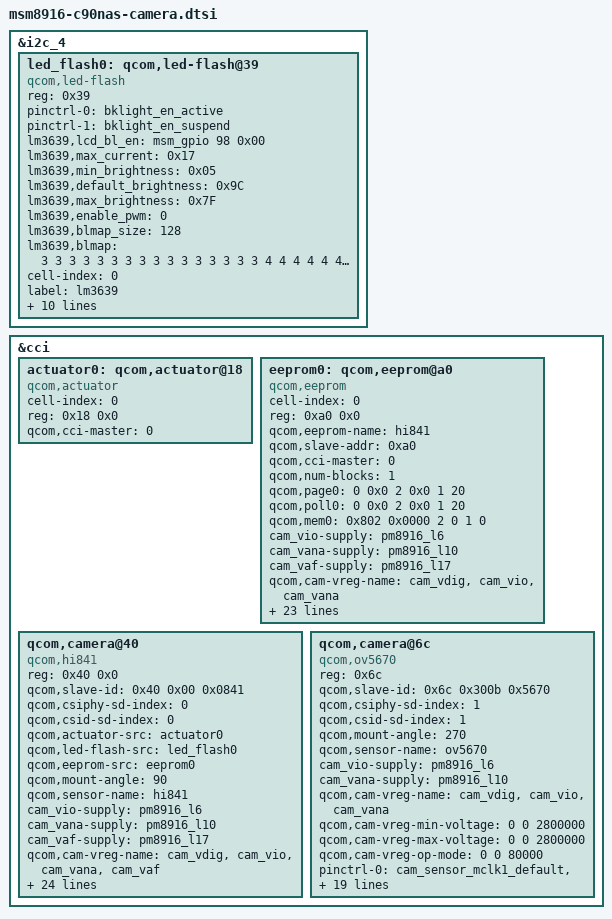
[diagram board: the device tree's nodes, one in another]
/*
 * Copyright (c) 2013, The Linux Foundation. All rights reserved.
 *
 * This program is free software; you can redistribute it and/or modify
 * it under the terms of the GNU General Public License version 2 and
 * only version 2 as published by the Free Software Foundation.
 *
 * This program is distributed in the hope that it will be useful,
 * but WITHOUT ANY WARRANTY; without even the implied warranty of
 * MERCHANTABILITY or FITNESS FOR A PARTICULAR PURPOSE.  See the
 * GNU General Public License for more details.
 */

&i2c_4 {
	led_flash0: qcom,led-flash@39 {
		compatible = "qcom,led-flash";
		status = "ok";
		reg = <0x39>;

		pinctrl-names = "default", "sleep";
		pinctrl-0 = <&bklight_en_active>;
		pinctrl-1 = <&bklight_en_suspend>;

		lm3639,lcd_bl_en = <&msm_gpio 98 0x00>;
		lm3639,max_current = <0x17>;
		lm3639,min_brightness = <0x05>;
		lm3639,default_brightness = <0x9C>;
		lm3639,max_brightness = <0x7F>;
		lm3639,enable_pwm = <0>;
		lm3639,blmap_size = <128>;
		lm3639,blmap = <
			3 3 3 3 3 3 3 3 3 3
			3 3 3 3 3 3 4 4 4 4
			4 4 4 5 5 5 5 5 6 6
			6 6 7 7 8 8 8 8 9 9
			10 10 10 11 11 12 13 13 13 14
			15 15 15 16 17 18 19 19 19 20
			21 22 23 23 24 25 26 26 27 28
			29 30 31 33 33 34 35 36 37 37
			38 39 41 42 43 43 45 46 48 49
			49 51 52 54 55 57 57 59 60 62
			64 64 66 67 69 71 73 73 75 77
			79 81 81 83 85 88 88 90 92 94
			96 99 101 101 104 106 108 111>;

		cell-index = <0>;
		label                   = "lm3639";
		qcom,flash-name         = "lm3639";
		qcom,slave-id           = <0x39 0x00 0x0011>;
		qcom,flash-type         = <1>;              // LED_FLASH
		qcom,gpio-no-mux        = <0>;
		gpios                   = <&msm_gpio 31 0>; // FLASH_STROBE_TRIG, GPIO 31
		qcom,gpio-flash-en      = <0>;
		qcom,gpio-req-tbl-num   = <0>;
		qcom,gpio-req-tbl-flags = <0>;
		qcom,gpio-req-tbl-label = "FLASH_EN";
		qcom,cci-master = <0>;
	};
};

&cci {

	actuator0: qcom,actuator@18 {
		cell-index = <0>;
		reg = <0x18 0x0>;
		compatible = "qcom,actuator";
		qcom,cci-master = <0>;
	};

	eeprom0: qcom,eeprom@a0 {
		cell-index = <0>;
		reg = <0xa0 0x0>;
		qcom,eeprom-name = "hi841";
		compatible = "qcom,eeprom";
		qcom,slave-addr = <0xa0>;
		qcom,cci-master = <0>;
		qcom,num-blocks = <1>;

		qcom,page0 = <0 0x0 2 0x0 1 20>;
		qcom,poll0 = <0 0x0 2 0x0 1 20>;
		qcom,mem0 = <0x802 0x0000 2 0 1 0>;

		//qcom,i2c-freq-mode = <1>; //I2C_FAST_MODE

		cam_vio-supply = <&pm8916_l6>;   //1V8_VREG_L6
		cam_vana-supply = <&pm8916_l10>; //2V8_VREG_L10
		cam_vaf-supply = <&pm8916_l17>;  //2V85_VREG_L17
		qcom,cam-vreg-name = "cam_vdig", "cam_vio", "cam_vana";
		qcom,cam-vreg-min-voltage = <0 0 2800000>;
		qcom,cam-vreg-max-voltage = <0 0 2800000>;
		qcom,cam-vreg-op-mode = <0 0 80000>;

		pinctrl-names = "cam_default", "cam_suspend";
		pinctrl-0 = <&cam_sensor_mclk0_default &cam_sensor_rear_default>;
		pinctrl-1 = <&cam_sensor_mclk0_sleep &cam_sensor_rear_sleep>;

		gpios = <&msm_gpio 26 0>,	//MAIN_CAM_MCLK
			<&msm_gpio 35 0>,		//MAIN_RESET_N
			<&msm_gpio 121 0>;		//CAM_DVDD_1V2,  LDO12_EN=GPIO_121

		qcom,gpio-no-mux = <0>;
		qcom,gpio-reset  = <1>;
		qcom,gpio-vdig   = <2>;     // CAM_DVDD_1V2
		qcom,gpio-req-tbl-num = <0 1 2>;
		qcom,gpio-req-tbl-flags = <1 0 0>;
		qcom,gpio-req-tbl-label = "CAMIF_MCLK", "CAM_RESET1", "CAM_DVDD";
		qcom,csi-lane-assign = <0x4320>;
		qcom,csi-lane-mask = <0x1F>;

		qcom,cam-power-seq-type = "sensor_vreg", "sensor_vreg", "sensor_gpio", "sensor_gpio";
		qcom,cam-power-seq-val  = "cam_vio", "cam_vana", "sensor_gpio_vdig", "sensor_gpio_reset";
		qcom,cam-power-seq-cfg-val = <0 0 1 1>;
		qcom,cam-power-seq-delay   = <1 0 0 10>;
	};

	qcom,camera@40 {
		compatible = "qcom,hi841";
		reg = <0x40 0x0>;
		qcom,slave-id = <0x40 0x00 0x0841>;
		qcom,csiphy-sd-index = <0>;
		qcom,csid-sd-index = <0>;
		qcom,actuator-src = <&actuator0>;
		qcom,led-flash-src = <&led_flash0>;
		qcom,eeprom-src = <&eeprom0>;
		qcom,mount-angle = <90>;
		qcom,sensor-name = "hi841";

		cam_vio-supply = <&pm8916_l6>;   //1V8_VREG_L6 (always-on)
		cam_vana-supply = <&pm8916_l10>; //2V8_VREG_L10
		cam_vaf-supply = <&pm8916_l17>;  //2V85_VREG_L17
		qcom,cam-vreg-name = "cam_vdig", "cam_vio", "cam_vana", "cam_vaf";
		qcom,cam-vreg-min-voltage = <0 0 2800000 2850000>;
		qcom,cam-vreg-max-voltage = <0 0 2800000 2850000>;
		qcom,cam-vreg-op-mode = <0 0 80000 100000>;

		pinctrl-names = "cam_default", "cam_suspend";
		pinctrl-0 = <&cam_sensor_mclk0_default &cam_sensor_rear_default>;
		pinctrl-1 = <&cam_sensor_mclk0_sleep &cam_sensor_rear_sleep>;

		gpios = <&msm_gpio 26 0>,	//MAIN_CAM_MCLK
			<&msm_gpio 35 0>,		//MAIN_RESET_N
			<&msm_gpio 121 0>;		//CAM_DVDD_1V2,  LDO12_EN=GPIO_121

		qcom,gpio-no-mux = <0>;
		qcom,gpio-reset  = <1>;
		qcom,gpio-vdig   = <2>;     // CAM_DVDD_1V2
		qcom,gpio-req-tbl-num = <0 1 2>;
		qcom,gpio-req-tbl-flags = <1 0 0>;
		qcom,gpio-req-tbl-label = "CAMIF_MCLK", "CAM_RESET1", "CAM_DVDD";
		qcom,csi-lane-assign = <0x4320>;
		qcom,csi-lane-mask = <0x1F>;
		qcom,sensor-position = <0>;
		qcom,sensor-mode = <0>;
		qcom,cci-master = <0>;
		qcom,mclk-23880000;
		lge,vcm-pwdn = "dw9718";
		status = "ok";
		clocks = <&clock_gcc clk_mclk0_clk_src>,
				 <&clock_gcc clk_gcc_camss_mclk0_clk>;
		clock-names = "cam_src_clk", "cam_clk";
	};

	qcom,camera@6c {
		compatible           = "qcom,ov5670";
		reg                  = <0x6c>;
		qcom,slave-id        = <0x6c 0x300b 0x5670>;
		qcom,csiphy-sd-index = <1>;
		qcom,csid-sd-index   = <1>; //<0>
		qcom,mount-angle     = <270>;
		qcom,sensor-name     = "ov5670";

		cam_vio-supply  = <&pm8916_l6>;   //1V8_VREG_L6 (always-on)
		cam_vana-supply = <&pm8916_l10>;  //2V8_VREG_L10
		qcom,cam-vreg-name = "cam_vdig", "cam_vio", "cam_vana";
		qcom,cam-vreg-min-voltage = <0 0 2800000>;
		qcom,cam-vreg-max-voltage = <0 0 2800000>;
		qcom,cam-vreg-op-mode     = <0 0   80000>;

		pinctrl-names = "cam_default", "cam_suspend";
		pinctrl-0 = <&cam_sensor_mclk1_default &cam_sensor_front_default>;
		pinctrl-1 = <&cam_sensor_mclk1_sleep &cam_sensor_front_sleep>;

		gpios = <&msm_gpio 27  0>,    //VT_CAM_MCLK,    GPIO 27
		        <&msm_gpio 28  0>,    //VT_CAM_RESET_N, GPIO 33
				<&msm_gpio 121 0>;	  //CAM_DVDD_1V2,   GPIO_121

		qcom,gpio-no-mux  = <0>;
		qcom,gpio-reset   = <1>;
		qcom,gpio-vdig    = <2>;

		qcom,gpio-req-tbl-num   = <0 1 2>;
		qcom,gpio-req-tbl-flags = <1 0 0>;
		qcom,gpio-req-tbl-label = "CAMIF_MCLK2",
		                          "CAM_RESET2",
		                          "MAIN_VDIG_EN2";

		qcom,csi-lane-assign    = <0x4320>;
		qcom,csi-lane-mask      = <0x7>;
		qcom,sensor-position    = <1>;
		qcom,sensor-mode        = <1>;
		qcom,cci-master         = <0>;
		qcom,mclk-23880000;

		status = "ok";
		clocks = <&clock_gcc clk_mclk1_clk_src>,
		         <&clock_gcc clk_gcc_camss_mclk1_clk>;
		clock-names = "cam_src_clk", "cam_clk";
	};
};
